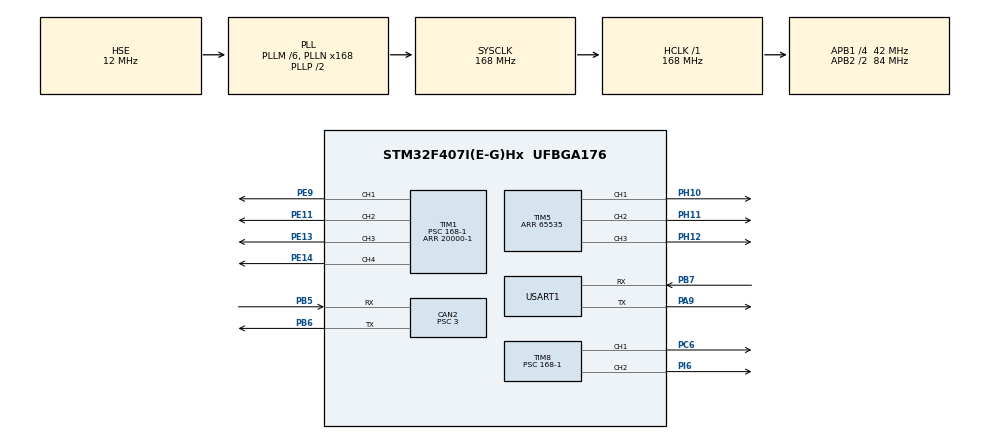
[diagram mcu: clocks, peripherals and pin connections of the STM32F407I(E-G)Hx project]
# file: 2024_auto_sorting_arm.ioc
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CAN2.BS1=CAN_BS1_10TQ
CAN2.BS2=CAN_BS2_3TQ
CAN2.CalculateBaudRate=1000000
CAN2.CalculateTimeBit=1000
CAN2.CalculateTimeQuantum=71.42857142857143
CAN2.Prescaler=3
FREERTOS.Tasks01=start_task,3,256,Start_Task,As weak,NULL,Dynamic,NULL,NULL;arm_task,1,256,Arm_Task,As weak,NULL,Dynamic,NULL,NULL;total_task,2,256,Total_Task,As weak,NULL,Dynamic,NULL,NULL
Mcu.Family=STM32F4
Mcu.Name=STM32F407I(E-G)Hx
Mcu.Package=UFBGA176
NVIC.CAN2_RX0_IRQn=true\:5\:0\:false\:false\:true\:true\:true\:true\:true
NVIC.PriorityGroup=NVIC_PRIORITYGROUP_4
NVIC.TIM7_IRQn=true\:15\:0\:false\:false\:true\:false\:false\:true\:true
NVIC.TimeBase=TIM7_IRQn
NVIC.TimeBaseIP=TIM7
PA13.Mode=Serial_Wire
PA13.Signal=SYS_JTMS-SWDIO
PA14.Mode=Serial_Wire
PA14.Signal=SYS_JTCK-SWCLK
PA9.Mode=Asynchronous
PA9.Signal=USART1_TX
PB5.Mode=CAN_Activate
PB5.Signal=CAN2_RX
PB6.Mode=CAN_Activate
PB6.Signal=CAN2_TX
PB7.Mode=Asynchronous
PB7.Signal=USART1_RX
PC6.Signal=S_TIM8_CH1
PD0.Signal=CAN1_RX
PD1.Signal=CAN1_TX
PE11.Signal=S_TIM1_CH2
PE13.Signal=S_TIM1_CH3
PE14.Signal=S_TIM1_CH4
PE9.Signal=S_TIM1_CH1
PH0-OSC_IN.Mode=HSE-External-Oscillator
PH0-OSC_IN.Signal=RCC_OSC_IN
PH1-OSC_OUT.Mode=HSE-External-Oscillator
PH1-OSC_OUT.Signal=RCC_OSC_OUT
PH10.Signal=S_TIM5_CH1
PH11.Signal=S_TIM5_CH2
PH12.Signal=S_TIM5_CH3
PI6.Signal=S_TIM8_CH2
ProjectManager.HeapSize=0x200
ProjectManager.StackSize=0x400
ProjectManager.TargetToolchain=MDK-ARM V5.32
RCC.48MHZClocksFreq_Value=84000000
RCC.AHBFreq_Value=168000000
RCC.APB1CLKDivider=RCC_HCLK_DIV4
RCC.APB1Freq_Value=42000000
RCC.APB1TimFreq_Value=84000000
RCC.APB2CLKDivider=RCC_HCLK_DIV2
RCC.APB2Freq_Value=84000000
RCC.APB2TimFreq_Value=168000000
RCC.CortexFreq_Value=168000000
RCC.HCLKFreq_Value=168000000
RCC.HSE_VALUE=12000000
RCC.HSI_VALUE=16000000
RCC.LSE_VALUE=32768
RCC.PLLM=6
RCC.PLLN=168
RCC.PLLSourceVirtual=RCC_PLLSOURCE_HSE
RCC.SYSCLKFreq_VALUE=168000000
RCC.SYSCLKSource=RCC_SYSCLKSOURCE_PLLCLK
RCC.VCOOutputFreq_Value=336000000
SH.S_TIM1_CH1.0=TIM1_CH1,PWM Generation1 CH1
SH.S_TIM1_CH2.0=TIM1_CH2,PWM Generation2 CH2
SH.S_TIM1_CH3.0=TIM1_CH3,PWM Generation3 CH3
SH.S_TIM1_CH4.0=TIM1_CH4,PWM Generation4 CH4
SH.S_TIM5_CH1.0=TIM5_CH1,PWM Generation1 CH1
SH.S_TIM5_CH2.0=TIM5_CH2,PWM Generation2 CH2
SH.S_TIM5_CH3.0=TIM5_CH3,PWM Generation3 CH3
SH.S_TIM8_CH1.0=TIM8_CH1,PWM Generation1 CH1
SH.S_TIM8_CH2.0=TIM8_CH2,PWM Generation2 CH2
TIM1.Channel-PWM\ Generation1\ CH1=TIM_CHANNEL_1
TIM1.Channel-PWM\ Generation2\ CH2=TIM_CHANNEL_2
TIM1.Channel-PWM\ Generation3\ CH3=TIM_CHANNEL_3
TIM1.Channel-PWM\ Generation4\ CH4=TIM_CHANNEL_4
TIM1.Period=20000-1
TIM1.Prescaler=168-1
TIM5.Channel-PWM\ Generation1\ CH1=TIM_CHANNEL_1
TIM5.Channel-PWM\ Generation2\ CH2=TIM_CHANNEL_2
TIM5.Channel-PWM\ Generation3\ CH3=TIM_CHANNEL_3
TIM5.Period=65535
TIM8.Channel-PWM\ Generation1\ CH1=TIM_CHANNEL_1
TIM8.Channel-PWM\ Generation2\ CH2=TIM_CHANNEL_2
TIM8.Period=20000-1
TIM8.Prescaler=168-1
USART1.VirtualMode=VM_ASYNC
VP_FREERTOS_VS_CMSIS_V1.Mode=CMSIS_V1
VP_SYS_VS_tim7.Mode=TIM7
VP_TIM1_VS_ClockSourceINT.Mode=Internal
VP_TIM5_VS_ClockSourceINT.Mode=Internal
VP_TIM8_VS_ClockSourceINT.Mode=Internal
board=custom

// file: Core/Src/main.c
/* USER CODE BEGIN Header */
/**
  ******************************************************************************
  * @file           : main.c
  * @brief          : Main program body
  ******************************************************************************
  * @attention
  *
  * Copyright (c) 2024 STMicroelectronics.
  * All rights reserved.
  *
  * This software is licensed under terms that can be found in the LICENSE file
  * in the root directory of this software component.
  * If no LICENSE file comes with this software, it is provided AS-IS.
  *
  ******************************************************************************
  */
/* USER CODE END Header */
#include "main.h"
#include "cmsis_os.h"
#include "can.h"
#include "tim.h"
#include "usart.h"
#include "gpio.h"

/* USER CODE BEGIN Includes */
#include "Includes.h"

/* USER CODE END Includes */

void SystemClock_Config(void);
void MX_FREERTOS_Init(void);

int main(void)
{

  /* MCU Configuration--------------------------------------------------------*/

  /* Reset of all peripherals, Initializes the Flash interface and the Systick. */
  HAL_Init();

  /* Configure the system clock */
  SystemClock_Config();

  /* Initialize all configured peripherals */
  MX_GPIO_Init();
  MX_CAN2_Init();
  MX_USART1_UART_Init();
  MX_TIM1_Init();
  MX_TIM8_Init();
  MX_TIM5_Init();

  /* Call init function for freertos objects (in cmsis_os2.c) */
  MX_FREERTOS_Init();

  /* Start scheduler */
  osKernelStart();

  /* We should never get here as control is now taken by the scheduler */

  /* Infinite loop */
  while (1)
  {

  }
}

void SystemClock_Config(void)
{
  RCC_OscInitTypeDef RCC_OscInitStruct = {0};
  RCC_ClkInitTypeDef RCC_ClkInitStruct = {0};

  /** Configure the main internal regulator output voltage
  */
  __HAL_RCC_PWR_CLK_ENABLE();
  __HAL_PWR_VOLTAGESCALING_CONFIG(PWR_REGULATOR_VOLTAGE_SCALE1);

  /** Initializes the RCC Oscillators according to the specified parameters
  * in the RCC_OscInitTypeDef structure.
  */
  RCC_OscInitStruct.OscillatorType = RCC_OSCILLATORTYPE_HSE;
  RCC_OscInitStruct.HSEState = RCC_HSE_ON;
  RCC_OscInitStruct.PLL.PLLState = RCC_PLL_ON;
  RCC_OscInitStruct.PLL.PLLSource = RCC_PLLSOURCE_HSE;
  RCC_OscInitStruct.PLL.PLLM = 6;
  RCC_OscInitStruct.PLL.PLLN = 168;
  RCC_OscInitStruct.PLL.PLLP = RCC_PLLP_DIV2;
  RCC_OscInitStruct.PLL.PLLQ = 4;
  if (HAL_RCC_OscConfig(&RCC_OscInitStruct) != HAL_OK)
  {
    Error_Handler();
  }

  /** Initializes the CPU, AHB and APB buses clocks
  */
  RCC_ClkInitStruct.ClockType = RCC_CLOCKTYPE_HCLK|RCC_CLOCKTYPE_SYSCLK
                              |RCC_CLOCKTYPE_PCLK1|RCC_CLOCKTYPE_PCLK2;
  RCC_ClkInitStruct.SYSCLKSource = RCC_SYSCLKSOURCE_PLLCLK;
  RCC_ClkInitStruct.AHBCLKDivider = RCC_SYSCLK_DIV1;
  RCC_ClkInitStruct.APB1CLKDivider = RCC_HCLK_DIV4;
  RCC_ClkInitStruct.APB2CLKDivider = RCC_HCLK_DIV2;

  if (HAL_RCC_ClockConfig(&RCC_ClkInitStruct, FLASH_LATENCY_5) != HAL_OK)
  {
    Error_Handler();
  }
}

void HAL_TIM_PeriodElapsedCallback(TIM_HandleTypeDef *htim)
{
  if (htim->Instance == TIM7) {
    HAL_IncTick();
  }
}

void Error_Handler(void)
{
  __disable_irq();
  while (1)
  {
  }
}
